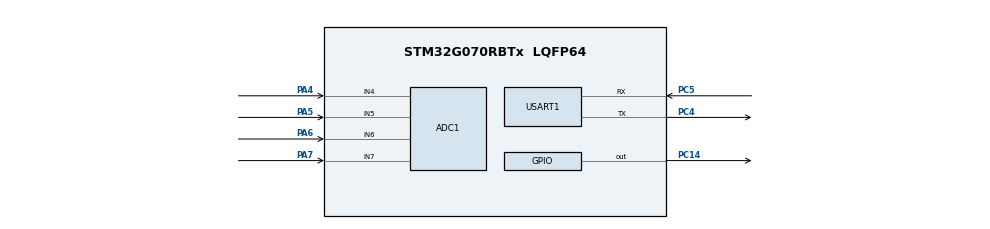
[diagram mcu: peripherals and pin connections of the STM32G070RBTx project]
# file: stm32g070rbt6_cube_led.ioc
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ADC1.Channel-5\#ChannelRegularConversion=ADC_CHANNEL_4
ADC1.Channel-6\#ChannelRegularConversion=ADC_CHANNEL_5
ADC1.Channel-7\#ChannelRegularConversion=ADC_CHANNEL_6
ADC1.Channel-8\#ChannelRegularConversion=ADC_CHANNEL_7
ADC1.Channel-9\#ChannelRegularConversion=ADC_CHANNEL_TEMPSENSOR
ADC1.ChannelTS=ADC_CHANNEL_TEMPSENSOR
ADC1.ClockPrescaler=ADC_CLOCK_ASYNC_DIV8
ADC1.ContinuousConvMode=ENABLE
ADC1.DMAContinuousRequests=ENABLE
ADC1.EOCSelection=ADC_EOC_SEQ_CONV
ADC1.NbrOfConversion=5
ADC1.NbrOfConversionFlag=1
ADC1.Rank-5\#ChannelRegularConversion=1
ADC1.Rank-6\#ChannelRegularConversion=2
ADC1.Rank-7\#ChannelRegularConversion=3
ADC1.Rank-8\#ChannelRegularConversion=4
ADC1.Rank-9\#ChannelRegularConversion=5
ADC1.SamplingTime-5\#ChannelRegularConversion=ADC_SAMPLINGTIME_COMMON_1
ADC1.SamplingTime-6\#ChannelRegularConversion=ADC_SAMPLINGTIME_COMMON_2
ADC1.SamplingTime-7\#ChannelRegularConversion=ADC_SAMPLINGTIME_COMMON_1
ADC1.SamplingTime-8\#ChannelRegularConversion=ADC_SAMPLINGTIME_COMMON_2
ADC1.SamplingTime-9\#ChannelRegularConversion=ADC_SAMPLINGTIME_COMMON_1
ADC1.SamplingTimeCommon1=ADC_SAMPLETIME_79CYCLES_5
ADC1.SamplingTimeCommon2=ADC_SAMPLETIME_79CYCLES_5
ADC1.SelectedChannel=ADC_CHANNEL_4|ADC_CHANNEL_5|ADC_CHANNEL_6|ADC_CHANNEL_7|ADC_CHANNEL_TEMPSENSOR
ADC1.master=1
Dma.ADC1.0.Direction=DMA_PERIPH_TO_MEMORY
Dma.ADC1.0.EventEnable=DISABLE
Dma.ADC1.0.Instance=DMA1_Channel1
Dma.ADC1.0.MemDataAlignment=DMA_MDATAALIGN_HALFWORD
Dma.ADC1.0.MemInc=DMA_MINC_ENABLE
Dma.ADC1.0.Mode=DMA_CIRCULAR
Dma.ADC1.0.PeriphDataAlignment=DMA_PDATAALIGN_HALFWORD
Dma.ADC1.0.PeriphInc=DMA_PINC_DISABLE
Dma.ADC1.0.Polarity=HAL_DMAMUX_REQ_GEN_RISING
Dma.ADC1.0.Priority=DMA_PRIORITY_LOW
Dma.ADC1.0.RequestNumber=1
Dma.ADC1.0.SignalID=NONE
Dma.ADC1.0.SyncEnable=DISABLE
Dma.ADC1.0.SyncPolarity=HAL_DMAMUX_SYNC_NO_EVENT
Dma.ADC1.0.SyncRequestNumber=1
Dma.ADC1.0.SyncSignalID=NONE
Dma.Request0=ADC1
Mcu.Family=STM32G0
Mcu.Name=STM32G070RBTx
Mcu.Package=LQFP64
NVIC.DMA1_Channel1_IRQn=true\:0\:0\:false\:false\:true\:false\:true\:true
NVIC.USART1_IRQn=true\:0\:0\:false\:false\:true\:true\:true\:true
PA13.Mode=Serial_Wire
PA13.Signal=SYS_SWDIO
PA14-BOOT0.Mode=Serial_Wire
PA14-BOOT0.Signal=SYS_SWCLK
PA4.Mode=IN4
PA4.Signal=ADC1_IN4
PA5.Mode=IN5
PA5.Signal=ADC1_IN5
PA6.Mode=IN6
PA6.Signal=ADC1_IN6
PA7.Mode=IN7
PA7.Signal=ADC1_IN7
PC14-OSC32_IN\ (PC14).Signal=GPIO_Output
PC4.Mode=Asynchronous
PC4.Signal=USART1_TX
PC5.Mode=Asynchronous
PC5.Signal=USART1_RX
PF0-OSC_IN\ (PF0).Mode=HSE-External-Oscillator
PF0-OSC_IN\ (PF0).Signal=RCC_OSC_IN
PF1-OSC_OUT\ (PF1).Mode=HSE-External-Oscillator
PF1-OSC_OUT\ (PF1).Signal=RCC_OSC_OUT
ProjectManager.HeapSize=0x200
ProjectManager.StackSize=0x400
ProjectManager.TargetToolchain=STM32CubeIDE
RCC.ADCFreq_Value=64000000
RCC.AHBFreq_Value=64000000
RCC.CortexFreq_Value=64000000
RCC.EXTERNAL_CLOCK_VALUE=48000
RCC.HCLKFreq_Value=64000000
RCC.HSE_VALUE=8000000
RCC.HSI_VALUE=16000000
RCC.LSE_VALUE=32768
RCC.SYSCLKFreq_VALUE=64000000
RCC.SYSCLKSource=RCC_SYSCLKSOURCE_PLLCLK
RCC.VCOOutputFreq_Value=128000000
USART1.AutoBaudRateEnableParam=UART_ADVFEATURE_AUTOBAUDRATE_ENABLE
USART1.AutoBaudRateMode=UART_ADVFEATURE_AUTOBAUDRATE_ON0X7FFRAME
USART1.DMADisableonRxErrorParam=ADVFEATURE_DMA_DISABLEONRXERROR
USART1.VirtualMode-Asynchronous=VM_ASYNC
VP_ADC1_TempSens_Input.Mode=IN-TempSens
VP_RTC_VS_RTC_Activate.Mode=RTC_Enabled
board=custom

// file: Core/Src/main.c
/* USER CODE BEGIN Header */
/**
  ******************************************************************************
  * @file           : main.c
  * @brief          : Main program body
  ******************************************************************************
  * @attention
  *
  * Copyright (c) 2022 STMicroelectronics.
  * All rights reserved.
  *
  * This software is licensed under terms that can be found in the LICENSE file
  * in the root directory of this software component.
  * If no LICENSE file comes with this software, it is provided AS-IS.
  *
  ******************************************************************************
  */
/* USER CODE END Header */
#include "main.h"
#include "adc.h"
#include "dma.h"
#include "rtc.h"
#include "usart.h"
#include "gpio.h"

/* USER CODE BEGIN PV */

extern ADC_HandleTypeDef hadc1;

#define ADC_CH_MAX    5
#define ADC_CH_1      0
#define ADC_CH_2      1
#define ADC_CH_3      2
#define ADC_CH_4      3
#define ADC_CH_TEMP   4

volatile uint16_t adc_data[ADC_CH_MAX] = {0,};

/* USER CODE END PV */

void SystemClock_Config(void);

int main(void)
{

  /* MCU Configuration--------------------------------------------------------*/

  /* Reset of all peripherals, Initializes the Flash interface and the Systick. */
  HAL_Init();

  /* Configure the system clock */
  SystemClock_Config();

  /* Initialize all configured peripherals */
  MX_GPIO_Init();
  MX_DMA_Init();
  MX_USART1_UART_Init();
  MX_RTC_Init();
  MX_ADC1_Init();
  /* USER CODE BEGIN 2 */

  /*ADC DMA */

  HAL_StatusTypeDef ret_adc;
  ret_adc = HAL_ADC_Start_DMA(&hadc1, (uint32_t*)&adc_data[0], ADC_CH_MAX);
  if (ret_adc !=  HAL_OK)
  {
  	HAL_Delay(1000);
  }

  /* USER CODE END 2 */

  /* Infinite loop */
  while (1)
  {

    /* USER CODE BEGIN 3 */
  	HAL_GPIO_TogglePin(GPIOC, GPIO_PIN_14);

  	HAL_Delay(1000);

  }
  /* USER CODE END 3 */
}

void SystemClock_Config(void)
{
  LL_FLASH_SetLatency(LL_FLASH_LATENCY_2);
  while(LL_FLASH_GetLatency() != LL_FLASH_LATENCY_2)
  {
  }

  /* HSI configuration and activation */
  LL_RCC_HSI_Enable();
  while(LL_RCC_HSI_IsReady() != 1)
  {
  }

  /* LSI configuration and activation */
  LL_RCC_LSI_Enable();
  while(LL_RCC_LSI_IsReady() != 1)
  {
  }

  LL_PWR_EnableBkUpAccess();
  /* Main PLL configuration and activation */
  LL_RCC_PLL_ConfigDomain_SYS(LL_RCC_PLLSOURCE_HSI, LL_RCC_PLLM_DIV_1, 8, LL_RCC_PLLR_DIV_2);
  LL_RCC_PLL_Enable();
  LL_RCC_PLL_EnableDomain_SYS();
  while(LL_RCC_PLL_IsReady() != 1)
  {
  }

  /* Set AHB prescaler*/
  LL_RCC_SetAHBPrescaler(LL_RCC_SYSCLK_DIV_1);

  /* Sysclk activation on the main PLL */
  LL_RCC_SetSysClkSource(LL_RCC_SYS_CLKSOURCE_PLL);
  while(LL_RCC_GetSysClkSource() != LL_RCC_SYS_CLKSOURCE_STATUS_PLL)
  {
  }

  /* Set APB1 prescaler*/
  LL_RCC_SetAPB1Prescaler(LL_RCC_APB1_DIV_1);
  /* Update CMSIS variable (which can be updated also through SystemCoreClockUpdate function) */
  LL_SetSystemCoreClock(64000000);

   /* Update the time base */
  if (HAL_InitTick (TICK_INT_PRIORITY) != HAL_OK)
  {
    Error_Handler();
  }
}

void Error_Handler(void)
{
  __disable_irq();
  while (1)
  {
  }
}
